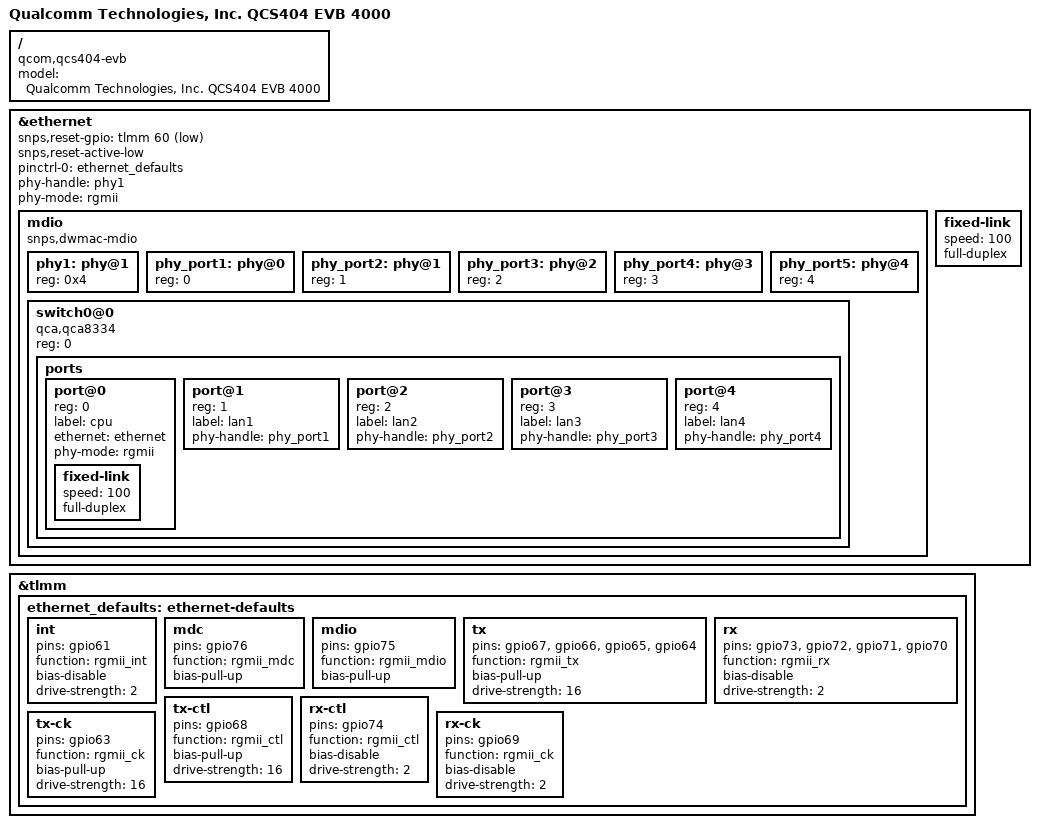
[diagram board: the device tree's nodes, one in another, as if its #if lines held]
// SPDX-License-Identifier: GPL-2.0
// Copyright (c) 2018, Linaro Limited

/dts-v1/;

#include "qcs404-evb.dtsi"

/ {
	model = "Qualcomm Technologies, Inc. QCS404 EVB 4000";
	compatible = "qcom,qcs404-evb";
};

#define AR8035

&ethernet {
	status = "ok";

	snps,reset-gpio = <&tlmm 60 GPIO_ACTIVE_LOW>;
	snps,reset-active-low;

	pinctrl-names = "default";
	pinctrl-0 = <&ethernet_defaults>;

#ifdef AR8035
	phy-handle = <&phy1>;
	phy-mode = "rgmii";
	mdio {
		#address-cells = <0x1>;
		#size-cells = <0x0>;
		compatible = "snps,dwmac-mdio";
		phy1: phy@1 {
			device_type = "ethernet-phy";
			reg = <0x4>;
		};
	};
#endif

#ifdef QCA8K

	fixed-link {
		speed = <100>;
		full-duplex;
	};

	mdio {
		phy_port1: phy@0 {
			reg = <0>;
		};

		phy_port2: phy@1 {
			reg = <1>;
		};

		phy_port3: phy@2 {
			reg = <2>;
		};

		phy_port4: phy@3 {
			reg = <3>;
		};

		phy_port5: phy@4 {
			reg = <4>;
		};

		switch0@0 {
			compatible = "qca,qca8334";
			#address-cells = <1>;
			#size-cells = <0>;

			reg = <0>;

			ports {
				#address-cells = <1>;
				#size-cells = <0>;
				port@0 {
					reg = <0>;
					label = "cpu";
					ethernet = <&ethernet>;
					phy-mode = "rgmii";
					fixed-link {
						speed = <100>;
						full-duplex;
					};
				};

				port@1 {
					reg = <1>;
					label = "lan1";
					phy-handle = <&phy_port1>;
				};

				port@2 {
					reg = <2>;
					label = "lan2";
					phy-handle = <&phy_port2>;
				};

				port@3 {
					reg = <3>;
					label = "lan3";
					phy-handle = <&phy_port3>;
				};

				port@4 {
					reg = <4>;
					label = "lan4";
					phy-handle = <&phy_port4>;
				};
			};
		};
	};
#endif

};

&tlmm {
	ethernet_defaults: ethernet-defaults {
		int {
			pins = "gpio61";
			function = "rgmii_int";
			bias-disable;
			drive-strength = <2>;
		};
		mdc {
			pins = "gpio76";
			function = "rgmii_mdc";
			bias-pull-up;
		};
		mdio {
			pins = "gpio75";
			function = "rgmii_mdio";
			bias-pull-up;
		};
		tx {
			pins = "gpio67", "gpio66", "gpio65", "gpio64";
			function = "rgmii_tx";
			bias-pull-up;
			drive-strength = <16>;
		};
		rx {
			pins = "gpio73", "gpio72", "gpio71", "gpio70";
			function = "rgmii_rx";
			bias-disable;
			drive-strength = <2>;
		};
		tx-ctl {
			pins = "gpio68";
			function = "rgmii_ctl";
			bias-pull-up;
			drive-strength = <16>;
		};
		rx-ctl {
			pins = "gpio74";
			function = "rgmii_ctl";
			bias-disable;
			drive-strength = <2>;
		};
		tx-ck {
			pins = "gpio63";
			function = "rgmii_ck";
			bias-pull-up;
			drive-strength = <16>;
		};
		rx-ck {
			pins = "gpio69";
			function = "rgmii_ck";
			bias-disable;
			drive-strength = <2>;
		};
	};
};
